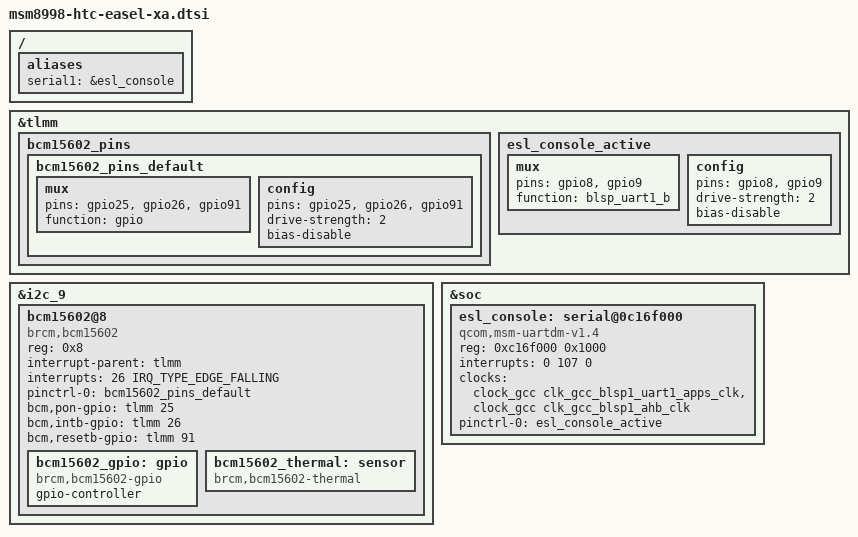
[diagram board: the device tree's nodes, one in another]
/* Copyright (c) 2016, The Linux Foundation. All rights reserved.
 *
 * This program is free software; you can redistribute it and/or modify
 * it under the terms of the GNU General Public License version 2 and
 * only version 2 as published by the Free Software Foundation.
 *
 * This program is distributed in the hope that it will be useful,
 * but WITHOUT ANY WARRANTY; without even the implied warranty of
 * MERCHANTABILITY or FITNESS FOR A PARTICULAR PURPOSE.  See the
 * GNU General Public License for more details.
 */

#include <dt-bindings/interrupt-controller/irq.h>

/ {
	aliases {
		serial1 = &esl_console;
	};
};

&tlmm {
	bcm15602_pins {
		bcm15602_pins_default: bcm15602_pins_default {
			mux {
				pins = "gpio25", "gpio26", "gpio91";
				function = "gpio";
			};

			config {
				pins = "gpio25", "gpio26", "gpio91";
				drive-strength = <2>;
				bias-disable;
			};
		};
	};

	esl_console_active: esl_console_active {
		mux {
			pins = "gpio8", "gpio9";
			function = "blsp_uart1_b";
		};

		config {
			pins = "gpio8", "gpio9";
			drive-strength = <2>;
			bias-disable;
		};
	};

};

&i2c_9 {
	bcm15602@8 {
		compatible = "brcm,bcm15602";
		reg = <0x8>;

		interrupt-parent = <&tlmm>;
		interrupts = <26 IRQ_TYPE_EDGE_FALLING>;
		interrupt-names = "bcm15602_intb";

		pinctrl-names = "default";
		pinctrl-0 = <&bcm15602_pins_default>;

		bcm,pon-gpio = <&tlmm 25 0x00>;
		bcm,intb-gpio = <&tlmm 26 0x00>;
		bcm,resetb-gpio = <&tlmm 91 0x00>;

		bcm15602_gpio: gpio {
			compatible = "brcm,bcm15602-gpio";
			gpio-controller;
			#gpio-cells = <2>;
		};

		bcm15602_thermal: sensor {
			compatible = "brcm,bcm15602-thermal";
			#thermal-sensor-cells = <0>;
		};
	};
};

&soc {
	esl_console: serial@0c16f000 {
		compatible = "qcom,msm-uartdm-v1.4", "qcom,msm-uartdm";
		reg = <0xc16f000 0x1000>;

		interrupts = <0 107 0>;

		clocks = <&clock_gcc clk_gcc_blsp1_uart1_apps_clk>,
			 <&clock_gcc clk_gcc_blsp1_ahb_clk>;
		clock-names = "core", "iface";

		pinctrl-names = "default";
		pinctrl-0 = <&esl_console_active>;
	};
};
